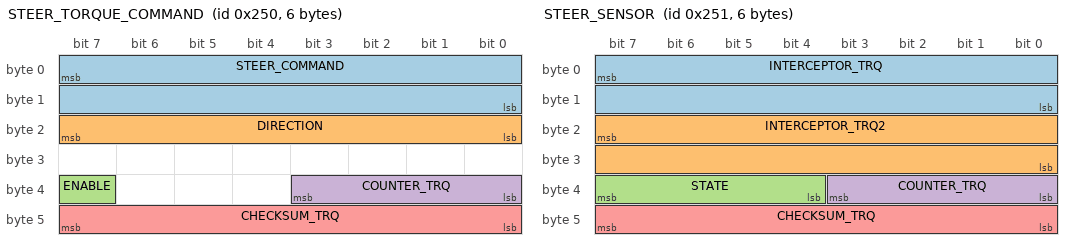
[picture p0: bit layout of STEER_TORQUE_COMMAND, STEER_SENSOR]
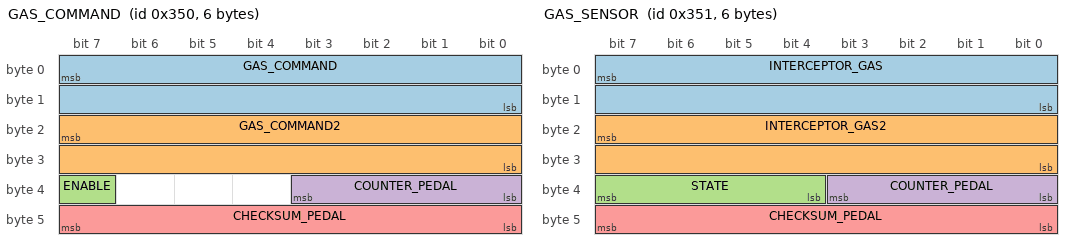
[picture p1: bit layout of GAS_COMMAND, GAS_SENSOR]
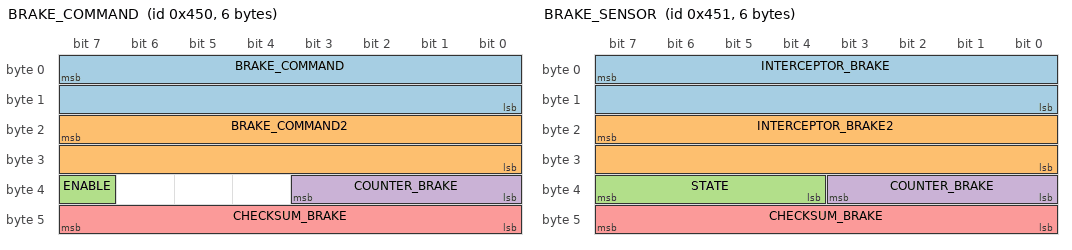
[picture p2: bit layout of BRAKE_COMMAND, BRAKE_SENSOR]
 BO_ 592 STEER_TORQUE_COMMAND: 6 EON
  SG_ STEER_COMMAND : 7|16@0+ (1,0) [0|1] "" INTERCEPTOR
  SG_ DIRECTION : 23|8@0+ (1,0) [0|1] "" INTERCEPTOR
  SG_ ENABLE : 39|1@0+ (1,0) [0|1] "" INTERCEPTOR
  SG_ COUNTER_TRQ : 35|4@0+ (1,0) [0|15] "" INTERCEPTOR
  SG_ CHECKSUM_TRQ : 47|8@0+ (1,0) [0|255] "" INTERCEPTOR

 BO_ 593 STEER_SENSOR: 6 INTERCEPTOR
  SG_ INTERCEPTOR_TRQ : 7|16@0+ (0.159375,-75.555) [0|1] "" EON
  SG_ INTERCEPTOR_TRQ2 : 23|16@0+ (0.159375,-151.111) [0|1] "" EON
  SG_ STATE : 39|4@0+ (1,0) [0|15] "" EON
  SG_ COUNTER_TRQ : 35|4@0+ (1,0) [0|15] "" EON
  SG_ CHECKSUM_TRQ : 47|8@0+ (1,0) [0|255] "" EON

 VAL_ 593 STATE 5 "FAULT_TIMEOUT" 4 "FAULT_STARTUP" 3 "FAULT_SCE" 2 "FAULT_SEND" 1 "FAULT_BAD_CHECKSUM" 0 "NO_FAULT" ;

 BO_ 848 GAS_COMMAND: 6 EON
  SG_ GAS_COMMAND : 7|16@0+ (0.159375,-75.555) [0|1] "" INTERCEPTOR
  SG_ GAS_COMMAND2 : 23|16@0+ (0.159375,-151.111) [0|1] "" INTERCEPTOR
  SG_ ENABLE : 39|1@0+ (1,0) [0|1] "" INTERCEPTOR
  SG_ COUNTER_PEDAL : 35|4@0+ (1,0) [0|15] "" INTERCEPTOR
  SG_ CHECKSUM_PEDAL : 47|8@0+ (1,0) [0|255] "" INTERCEPTOR

 BO_ 849 GAS_SENSOR: 6 INTERCEPTOR
  SG_ INTERCEPTOR_GAS : 7|16@0+ (0.159375,-75.555) [0|1] "" EON
  SG_ INTERCEPTOR_GAS2 : 23|16@0+ (0.159375,-151.111) [0|1] "" EON
  SG_ STATE : 39|4@0+ (1,0) [0|15] "" EON
  SG_ COUNTER_PEDAL : 35|4@0+ (1,0) [0|15] "" EON
  SG_ CHECKSUM_PEDAL : 47|8@0+ (1,0) [0|255] "" EON

 VAL_ 849 STATE 5 "FAULT_TIMEOUT" 4 "FAULT_STARTUP" 3 "FAULT_SCE" 2 "FAULT_SEND" 1 "FAULT_BAD_CHECKSUM" 0 "NO_FAULT" ;

 BO_ 1104 BRAKE_COMMAND: 6 EON
  SG_ BRAKE_COMMAND : 7|16@0+ (0.159375,-75.555) [0|1] "" INTERCEPTOR
  SG_ BRAKE_COMMAND2 : 23|16@0+ (0.159375,-151.111) [0|1] "" INTERCEPTOR
  SG_ ENABLE : 39|1@0+ (1,0) [0|1] "" INTERCEPTOR
  SG_ COUNTER_BRAKE : 35|4@0+ (1,0) [0|15] "" INTERCEPTOR
  SG_ CHECKSUM_BRAKE : 47|8@0+ (1,0) [0|255] "" INTERCEPTOR

 BO_ 1105 BRAKE_SENSOR: 6 INTERCEPTOR
  SG_ INTERCEPTOR_BRAKE : 7|16@0+ (0.159375,-75.555) [0|1] "" EON
  SG_ INTERCEPTOR_BRAKE2 : 23|16@0+ (0.159375,-151.111) [0|1] "" EON
  SG_ STATE : 39|4@0+ (1,0) [0|15] "" EON
  SG_ COUNTER_BRAKE : 35|4@0+ (1,0) [0|15] "" EON
  SG_ CHECKSUM_BRAKE : 47|8@0+ (1,0) [0|255] "" EON

 VAL_ 1105 STATE 5 "FAULT_TIMEOUT" 4 "FAULT_STARTUP" 3 "FAULT_SCE" 2 "FAULT_SEND" 1 "FAULT_BAD_CHECKSUM" 0 "NO_FAULT" ;

VERSION ""

NS_ :

BS_:

BU_: XXX

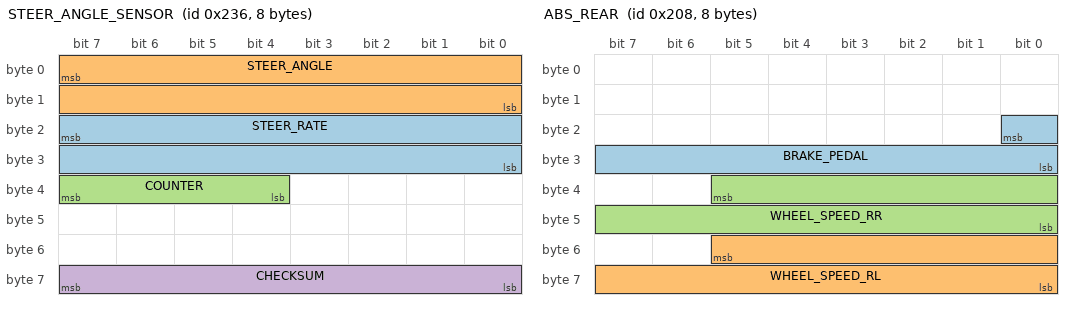
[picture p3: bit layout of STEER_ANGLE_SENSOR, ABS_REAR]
BO_ 566 STEER_ANGLE_SENSOR: 8 XXX
 SG_ STEER_RATE : 23|16@0- (0.5,-2048) [0|65535] "" XXX
 SG_ STEER_ANGLE : 7|16@0- (0.5,-2048) [0|65535] "deg" XXX
 SG_ COUNTER : 39|4@0+ (1,0) [0|15] "" XXX
 SG_ CHECKSUM : 63|8@0+ (1,0) [0|255] "" XXX

BO_ 664 MOTOR: 8 XXX
 SG_ TEMPERATURE : 8|8@1+ (1,-40) [0|255] "" XXX
 SG_ RPM : 55|16@0- (0.018181818,-181.81818181) [0|65535] "" XXX

BO_ 754 STEER_TORQUE: 3 XXX
 SG_ TORQUE_SENSOR : 7|8@0+ (1,0) [0|65535] "nm" XXX

BO_ 528 GAS: 7 XXX
 SG_ GAS_PEDAL : 23|8@0+ (1,0) [0|65535] "" XXX

BO_ 520 ABS_REAR: 8 XXX
 SG_ BRAKE_PEDAL : 16|9@0+ (1,0) [0|255] "" XXX
 SG_ WHEEL_SPEED_RL : 53|14@0+ (1,0) [0|65535] "" XXX
 SG_ WHEEL_SPEED_RR : 37|14@0+ (1,0) [0|65535] "" XXX

BO_ 512 ABS_FRONT: 8 XXX
 SG_ WHEEL_SPEED_FL : 21|14@0+ (1,0) [0|16383] "" XXX
 SG_ WHEEL_SPEED_FR : 37|14@0+ (1,0) [0|16383] "" XXX

BO_ 561 BRAKE_PRESSED: 8 XXX
 SG_ BRAKE_PRESSED : 33|1@0+ (1,0) [0|1] "" XXX

BO_ 1042 COMBOMETER: 8 XXX
 SG_ SPEED : 15|8@0+ (1,0) [0|65535] "km/h" XXX
 SG_ ODOMETER : 23|24@0+ (1,0) [0|16777215] "" XXX

BO_ 1048 GEAR_PACKET: 7 XXX
 SG_ GEAR : 7|8@0+ (1,0) [0|255] "ascii" XXX

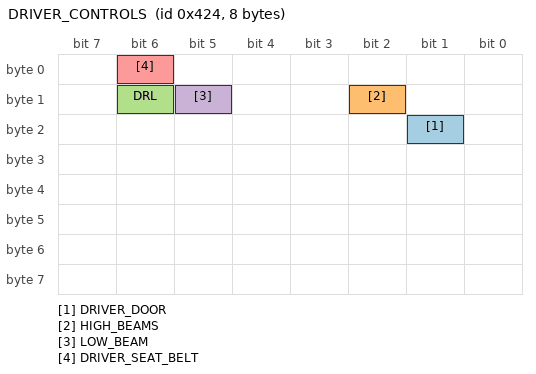
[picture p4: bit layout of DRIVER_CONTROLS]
BO_ 1060 DRIVER_CONTROLS: 8 XXX
 SG_ DRIVER_DOOR : 17|1@0+ (1,0) [0|1] "" XXX
 SG_ HIGH_BEAMS : 10|1@0+ (1,0) [0|1] "" XXX
 SG_ DRL : 14|1@0+ (1,0) [0|1] "" XXX
 SG_ LOW_BEAM : 13|1@0+ (1,0) [0|1] "" XXX
 SG_ DRIVER_SEAT_BELT : 6|1@0+ (1,0) [0|1] "" XXX

BO_ 883 POWER_DATA: 8 XXX
 SG_ BATTERY_CURRENT : 23|16@0+ (0.01,-327.68) [0|65535] "" XXX
 SG_ BATTERY_VOLTAGE : 39|16@0+ (0.1,0) [0|65535] "" XXX

BO_ 838 RANGE: 8 XXX
 SG_ RANGE : 63|8@0+ (1,0) [0|255] "" XXX

CM_ SG_ 1060 DRIVER_SEAT_BELT "1 is off 0 is on";
